# STM32F303x register map
File version: 1.0
Registers are 32-bit, read-write, reset 0x0 unless marked. A register's access mark holds for its fields unless they carry their own. Offsets are from the block's base; [hi:lo] are bit positions.

## RCC — Reset and clock control
Base 0x40021000
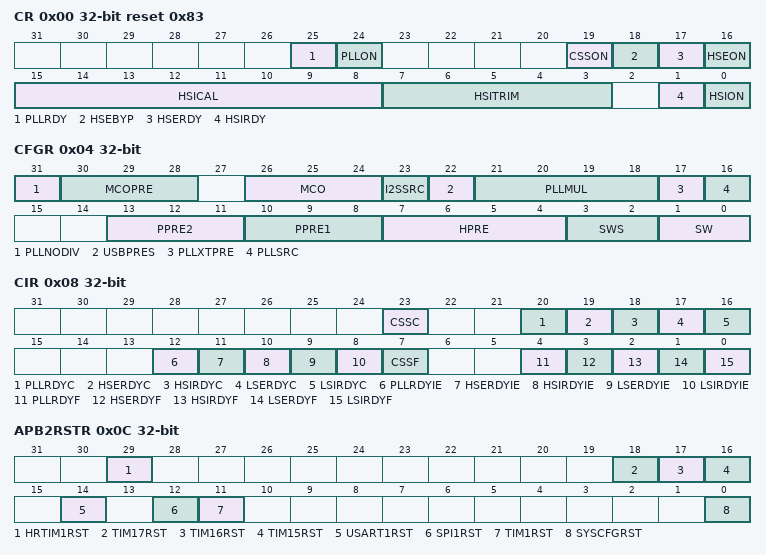
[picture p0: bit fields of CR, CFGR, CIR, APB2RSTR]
0x00 CR access per field reset 0x83 — Clock control register
  [25] PLLRDY ro — PLL clock ready flag
  [24] PLLON rw — PLL enable
  [19] CSSON rw — Clock Security System enable
  [18] HSEBYP rw — External High Speed clock Bypass
  [17] HSERDY ro — External High Speed clock ready flag
  [16] HSEON rw — External High Speed clock enable
  [15:8] HSICAL ro — Internal High Speed clock Calibration
  [7:3] HSITRIM rw — Internal High Speed clock trimming
  [1] HSIRDY ro — Internal High Speed clock ready flag
  [0] HSION rw — Internal High Speed clock enable
0x04 CFGR access per field — Clock configuration register (RCC_CFGR)
  [31] PLLNODIV rw
  [30:28] MCOPRE ro
  [26:24] MCO rw — Microcontroller clock output
  [23] I2SSRC rw — I2S external clock source selection
  [22] USBPRES rw — USB prescaler
  [21:18] PLLMUL rw — PLL Multiplication Factor
  [17] PLLXTPRE rw — HSE divider for PLL entry
  [16] PLLSRC rw — PLL entry clock source
  [13:11] PPRE2 rw — APB high speed prescaler (APB2)
  [10:8] PPRE1 rw — APB Low speed prescaler (APB1)
  [7:4] HPRE rw — AHB prescaler
  [3:2] SWS ro — System Clock Switch Status
  [1:0] SW rw — System clock Switch
0x08 CIR access per field — Clock interrupt register (RCC_CIR)
  [23] CSSC wo — Clock security system interrupt clear
  [20] PLLRDYC wo — PLL Ready Interrupt Clear
  [19] HSERDYC wo — HSE Ready Interrupt Clear
  [18] HSIRDYC wo — HSI Ready Interrupt Clear
  [17] LSERDYC wo — LSE Ready Interrupt Clear
  [16] LSIRDYC wo — LSI Ready Interrupt Clear
  [12] PLLRDYIE rw — PLL Ready Interrupt Enable
  [11] HSERDYIE rw — HSE Ready Interrupt Enable
  [10] HSIRDYIE rw — HSI Ready Interrupt Enable
  [9] LSERDYIE rw — LSE Ready Interrupt Enable
  [8] LSIRDYIE rw — LSI Ready Interrupt Enable
  [7] CSSF ro — Clock Security System Interrupt flag
  [4] PLLRDYF ro — PLL Ready Interrupt flag
  [3] HSERDYF ro — HSE Ready Interrupt flag
  [2] HSIRDYF ro — HSI Ready Interrupt flag
  [1] LSERDYF ro — LSE Ready Interrupt flag
  [0] LSIRDYF ro — LSI Ready Interrupt flag
0x0C APB2RSTR — APB2 peripheral reset register (RCC_APB2RSTR)
  [29] HRTIM1RST — HRTIM1 reset
  [18] TIM17RST — TIM17 timer reset
  [17] TIM16RST — TIM16 timer reset
  [16] TIM15RST — TIM15 timer reset
  [14] USART1RST — USART1 reset
  [12] SPI1RST — SPI 1 reset
  [11] TIM1RST — TIM1 timer reset
  [0] SYSCFGRST — SYSCFG and COMP reset
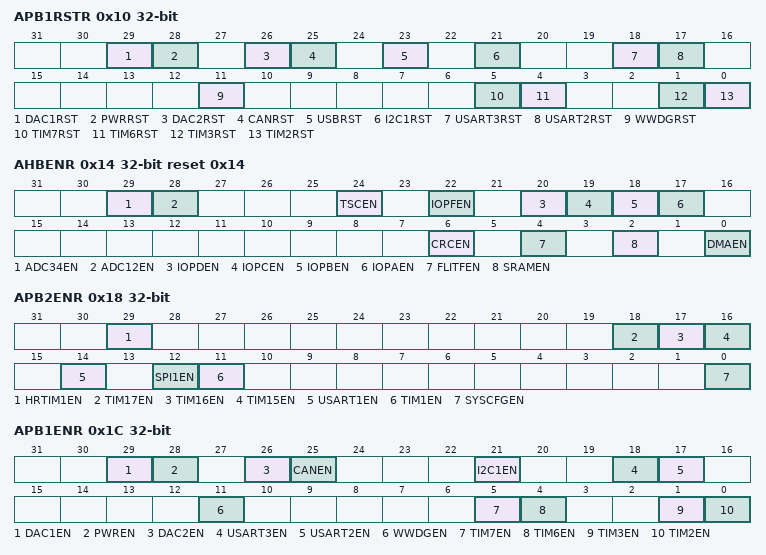
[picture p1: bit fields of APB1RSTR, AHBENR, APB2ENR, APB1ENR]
0x10 APB1RSTR — APB1 peripheral reset register (RCC_APB1RSTR)
  [29] DAC1RST — DAC1 interface reset
  [28] PWRRST — Power interface reset
  [26] DAC2RST — DAC2 interface reset
  [25] CANRST — CAN reset
  [23] USBRST — USB reset
  [21] I2C1RST — I2C1 reset
  [18] USART3RST — USART3 reset
  [17] USART2RST — USART 2 reset
  [11] WWDGRST — Window watchdog reset
  [5] TIM7RST — Timer 7 reset
  [4] TIM6RST — Timer 6 reset
  [1] TIM3RST — Timer 3 reset
  [0] TIM2RST — Timer 2 reset
0x14 AHBENR reset 0x14 — AHB Peripheral Clock enable register (RCC_AHBENR)
  [29] ADC34EN — ADC3 and ADC4 clock enable
  [28] ADC12EN — ADC1 and ADC2 clock enable
  [24] TSCEN — Touch sensing controller clock enable
  [22] IOPFEN — I/O port F clock enable
  [20] IOPDEN — I/O port D clock enable
  [19] IOPCEN — I/O port C clock enable
  [18] IOPBEN — I/O port B clock enable
  [17] IOPAEN — I/O port A clock enable
  [6] CRCEN — CRC clock enable
  [4] FLITFEN — FLITF clock enable
  [2] SRAMEN — SRAM interface clock enable
  [0] DMAEN — DMA1 clock enable
0x18 APB2ENR — APB2 peripheral clock enable register (RCC_APB2ENR)
  [29] HRTIM1EN — HRTIM1 clock enable
  [18] TIM17EN — TIM17 timer clock enable
  [17] TIM16EN — TIM16 timer clock enable
  [16] TIM15EN — TIM15 timer clock enable
  [14] USART1EN — USART1 clock enable
  [12] SPI1EN — SPI 1 clock enable
  [11] TIM1EN — TIM1 Timer clock enable
  [0] SYSCFGEN — SYSCFG clock enable
0x1C APB1ENR — APB1 peripheral clock enable register (RCC_APB1ENR)
  [29] DAC1EN — DAC1 interface clock enable
  [28] PWREN — Power interface clock enable
  [26] DAC2EN — DAC2 clock enable
  [25] CANEN — CAN clock enable
  [21] I2C1EN — I2C 1 clock enable
  [18] USART3EN — USART 3 clock enable
  [17] USART2EN — USART 2 clock enable
  [11] WWDGEN — Window watchdog clock enable
  [5] TIM7EN — Timer 7 clock enable
  [4] TIM6EN — Timer 6 clock enable
  [1] TIM3EN — Timer 3 clock enable
  [0] TIM2EN — Timer 2 clock enable
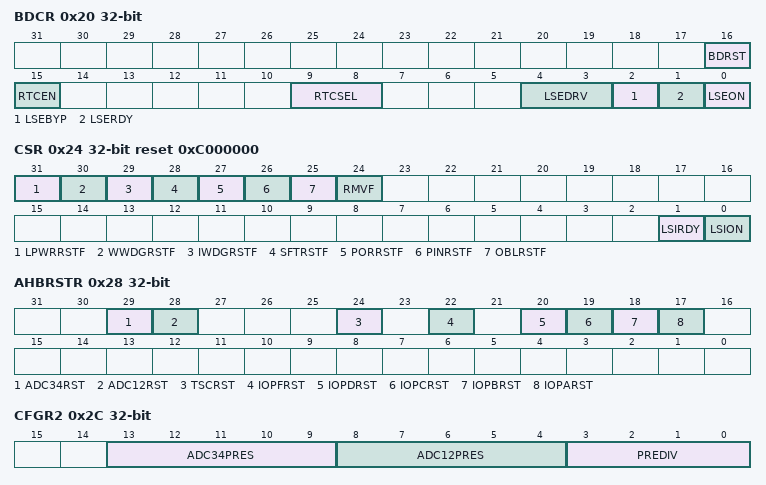
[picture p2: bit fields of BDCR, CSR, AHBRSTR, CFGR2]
0x20 BDCR access per field — Backup domain control register (RCC_BDCR)
  [16] BDRST rw — Backup domain software reset
  [15] RTCEN rw — RTC clock enable
  [9:8] RTCSEL rw — RTC clock source selection
  [4:3] LSEDRV rw — LSE oscillator drive capability
  [2] LSEBYP rw — External Low Speed oscillator bypass
  [1] LSERDY ro — External Low Speed oscillator ready
  [0] LSEON rw — External Low Speed oscillator enable
0x24 CSR access per field reset 0xC000000 — Control/status register (RCC_CSR)
  [31] LPWRRSTF rw — Low-power reset flag
  [30] WWDGRSTF rw — Window watchdog reset flag
  [29] IWDGRSTF rw — Independent watchdog reset flag
  [28] SFTRSTF rw — Software reset flag
  [27] PORRSTF rw — POR/PDR reset flag
  [26] PINRSTF rw — PIN reset flag
  [25] OBLRSTF rw — Option byte loader reset flag
  [24] RMVF rw — Remove reset flag
  [1] LSIRDY ro — Internal low speed oscillator ready
  [0] LSION rw — Internal low speed oscillator enable
0x28 AHBRSTR — AHB peripheral reset register
  [29] ADC34RST — ADC3 and ADC4 reset
  [28] ADC12RST — ADC1 and ADC2 reset
  [24] TSCRST — Touch sensing controller reset
  [22] IOPFRST — I/O port F reset
  [20] IOPDRST — I/O port D reset
  [19] IOPCRST — I/O port C reset
  [18] IOPBRST — I/O port B reset
  [17] IOPARST — I/O port A reset
0x2C CFGR2 — Clock configuration register 2
  [13:9] ADC34PRES — ADC3 and ADC4 prescaler
  [8:4] ADC12PRES — ADC1 and ADC2 prescaler
  [3:0] PREDIV — PREDIV division factor
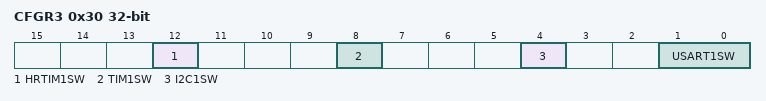
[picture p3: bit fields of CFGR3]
0x30 CFGR3 — Clock configuration register 3
  [12] HRTIM1SW — HRTIM1 clock selection
  [8] TIM1SW — Timer1 clock source selection
  [4] I2C1SW — I2C1 clock source selection
  [1:0] USART1SW — USART1 clock source selection
